# STM32MP23_CM33 register map
File version: 1.2
CPU: CM33 r0p1, little endian, MPU, FPU, vendor SysTick, 8 interrupt priority bits
Registers are 32-bit, read-write, reset 0x0 unless marked. A register's access mark holds for its fields unless they carry their own. Offsets are from the block's base; [hi:lo] are bit positions; {n}, {i} and the like mark numbered series; 'fields as' and 'values as' point back to an identical list.

## RISAF1 — RISAF register block
Base 0x420A0000
Same registers: RISAF2 0x420B0000, RISAF4 0x420D0000, RISAF5 0x420E0000, RISAF1_S 0x520A0000, RISAF2_S 0x520B0000, RISAF4_S 0x520D0000, RISAF5_S 0x520E0000
0x00 RISAF_CR — RISAF configuration register
  [0] GLOCK — Global lock This bit locks the configuration of RISAF registers until next reset. It is cleared by default, and, once set, cannot be reset until global RISAF reset.
    0=RISAF registers are writable; 1=All writes to RISAF registers are ignored, except RISAF_IACR, RISAF_REGx_zCFGR, RISAF_REGx_zSTARTR and RISAF_REGx_zENDR (z = A to B)
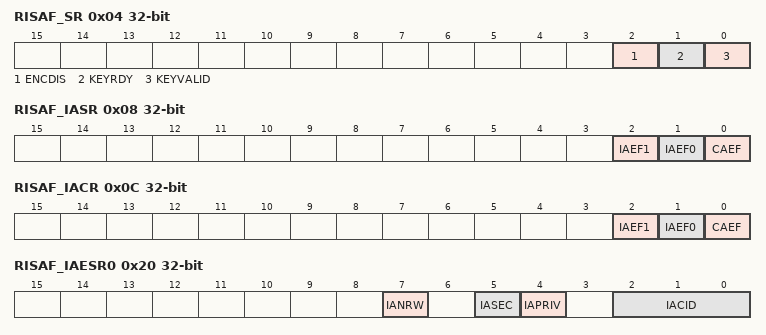
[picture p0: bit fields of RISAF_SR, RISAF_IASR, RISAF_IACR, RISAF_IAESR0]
0x04 RISAF_SR ro — RISAF status register
  [2] ENCDIS — Encryption disabled This bit is reserved if the encryption feature is not available in RISAF (see Section10.3). It is a non-volatile product configuration that cannot be changed by software. Note: If BREN = 0, the AES feature of RISAF is not usable for a given region.
    0=When ENC=BREN=1 in RISAF_REGx_CFGR, all allowed write accesses in region x are encrypted, and all allowed read requests are decrypted; 1=When ENC=BREN=1 in RISAF_REGx_CFGR, all write accesses in region x are ignored, and all read requests return 0. In other words, the AES feature of RISAF is unusable, for any region.
  [1] KEYRDY — Key ready This bit is reserved if the encryption feature is not available in RISAF (see Section10.3).
    0=The most recently written key in RISAF_KEYRy is being expanded; 1=The most recently written key in RISAF_KEYRy is ready for use
  [0] KEYVALID — Key valid This bit is reserved if the encryption feature is not available in RISAF (see Section10.3).
    0=A valid key has not been written in RISAF_KEYRy; 1=A valid key has been written in RISAF_KEYRy
0x08 RISAF_IASR ro — RISAF illegal access status register
  [2] IAEF1 — Illegal access error flag 1 This bit is reserved if the dual port feature is not available in the RISAF instance (see Section10.3). The bit is set when an illegal access is detected by checker unit 1 on the system bus. More details on the error can be found in RISAF_IAESR1 and RISAF_IADDR1. This bit is cleared by setting the corresponding bit in RISAF_IACR.
  [1] IAEF0 — Illegal access error flag 0 This bit is set when an illegal access is detected by checker unit 0 on the system bus. More details on the error can be found in RISAF_IAESR0 and RISAF_IADDR0. This bit is cleared by setting corresponding bit in RISAF_IACR.
  [0] CAEF — Configuration access error flag This bit is set when an illegal access to any RISAF configuration register is detected. It is cleared by setting the corresponding bit in RISAF_IACR.
0x0C RISAF_IACR wo — RISAF illegal access clear register
  [2] IAEF1 — Illegal access error flag 1 This bit is reserved if the dual port feature is not available in the RISAF instance (see Section10.3). Set this bit to clear IAEF1 in RISAF_IASR, allowing the capture of a new error information from RIF gate 1 in RISAF_IAESR1 and RISAF_IADDR1. Note: Clearing this bit does not clear RISAB_IADDR1.
  [1] IAEF0 — Illegal access error flag 0 Set this bit to clear IAEF0 in RISAF_IASR, allowing the capture of a new error information from RIF gate 0 in RISAF_IAESR0 and RISAF_IADDR0 registers. Note: Clearing this bit does not clear RISAB_IADDR0.
  [0] CAEF — Configuration access error flag Set this bit to clear CAEF in RISAF_IASR.
0x20 RISAF_IAESR0 ro — RISAF illegal access error status register 0
  [7] IANRW — Illegal access read/write When IAEFx = 1 in RISAF_IASR, IANRW captures the access type of the illegal access that has been detected by RIF gate x.
    0=Illegal access was a data read or an instruction fetch; 1=Illegal access was a data write
  [5] IASEC — Illegal access security When IAEFx = 1 in RISAF_IASR, IASEC captures the security type of the illegal access that has been detected by RIF gate x.
    0=Illegal access was non-secure; 1=Illegal access was secure
  [4] IAPRIV — Illegal access privileged When IAEFx = 1 in RISAF_IASR, IAPRIV captures the privilege state of the master that issued the illegal access detected by RIF gate x.
    0=Illegal access was unprivileged; 1=Illegal access was privileged
  [2:0] IACID — Illegal access compartment ID When IAEFx = 1 in RISAF_IASR, IACID[2:0] captures the compartment ID of the master that issued the illegal access detected by RIF gate x.
0x24 RISAF_IADDR0 ro — RISAF illegal address register 0
  [31:0] IADD — Illegal address When IAEFx = 1 in RISAFB_IASR, IADD[31:0] captures the address of the erroneous access through RIF gate x. Additional information can be found in RISAF_IAESRx Captured address information is the byte offset from the base of the protected address space.
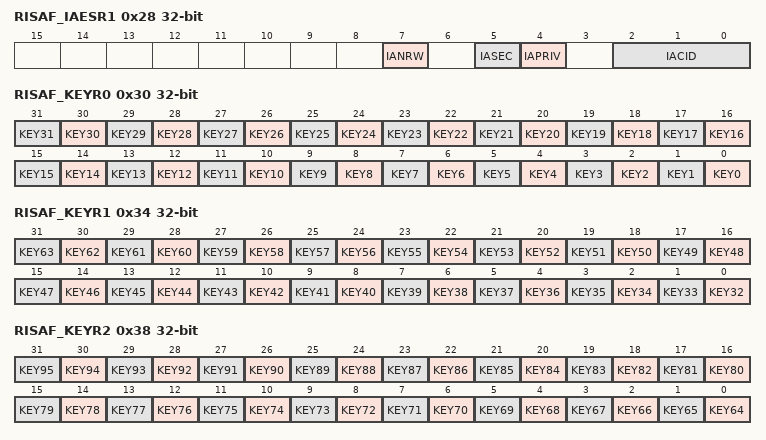
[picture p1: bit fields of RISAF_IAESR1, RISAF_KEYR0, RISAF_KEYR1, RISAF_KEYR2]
0x28 RISAF_IAESR1 ro — RISAF illegal access error status register 1
  fields as RISAF_IAESR0
0x2C RISAF_IADDR1 ro — RISAF illegal address register 1
  fields as RISAF_IADDR0
0x30 RISAF_KEYR0 wo — RISAF encryption key 0
  [n] KEY{n} (n=0..31) — Cryptographic key This write-only bit field contains the key used by the DDRMCE.
0x34 RISAF_KEYR1 wo — RISAF encryption key 1
  [n-32] KEY{n} (n=32..63) — Cryptographic key This write-only bit field contains the key used by the DDRMCE.
0x38 RISAF_KEYR2 wo — RISAF encryption key 2
  [n-64] KEY{n} (n=64..95) — Cryptographic key This write-only bit field contains the key used by the DDRMCE.
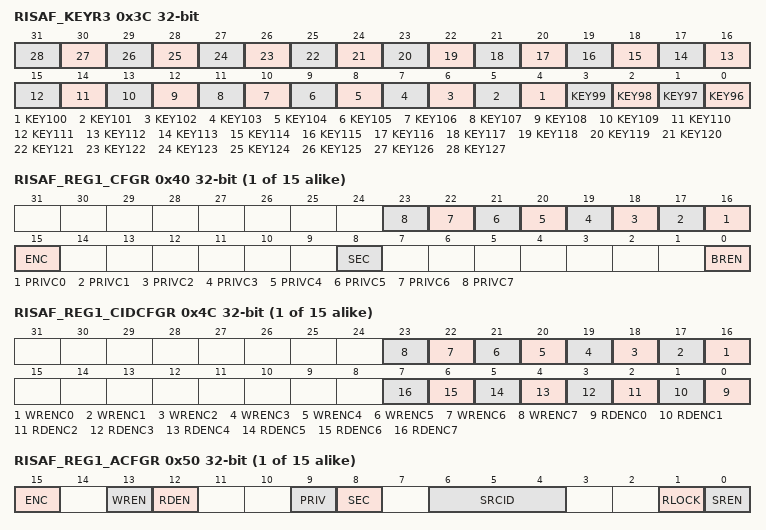
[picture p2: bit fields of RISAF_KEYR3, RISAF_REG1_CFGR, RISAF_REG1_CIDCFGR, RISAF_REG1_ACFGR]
0x3C RISAF_KEYR3 wo — RISAF encryption key 3
  [n-96] KEY{n} (n=96..127) — Cryptographic key This write-only bit field contains the key used by the DDRMCE.
{0x0+0x40*i} RISAF_REG{i}_CFGR (i=1..15) — RISAF region {i} configuration register
  [n+16] PRIVC{n} (n=0..7) — Privileged access for compartment y This bit is taken into account only if BREN = 1.
    0=Application running in compartment y can access to region x in privileged and unprivileged mode; 1=Application running in compartment y can access to region x in privileged mode only
  [15] ENC — Encrypted region This bit is taken into account only if BREN = 1 and if the DDRMCE feature is available in RISAF (see ENCDIS in RISAF_SR and Section10.3). Note: Key registers RISAF_KEYRy must be properly initialized before setting this bit (KEYVALID = 1 in RISAF_SR).
    0=No effect; 1=All allowed write accesses are encrypted and all allowed read requests are decrypted when KEYRDY = 1 in RISAF_SR (to be used for secure regions only)
  [8] SEC — Secure region This bit is taken into account only if BREN = 1.
    0=Only non-secure requests can access region x. SEC value in RISAF_REGx_zCFGR is internally treated as zeroed by RISAF (only non-secure requests to subregions).; 1=Only secure requests can access region x, and optional subregions can be defined as secure or non-secure
  [0] BREN — Base region enable Note: The filtering starts from start address RISAF_REGx_STARTR (included) and ends at end address RISAF_REGx_ENDR (included).
    0=Base region x is disabled. Access control of primary region 0 (secure, privileged, trusted domain TDCID) applies to any access between region x start and end addresses. Associated subregions are also disabled.; 1=Base region x is enabled. Access controls defined in region x apply to any access between region x start and end addresses.
{0x4+0x40*i} RISAF_REG{i}_STARTR (i=1..15) — RISAF region {i} start-address register
  [31:0] BADDSTART — Base region address start This bit field defines the byte-address offset (relative to the base address of the protected address space) of the lowest byte-address in base region x. Address bits less than the granularity and greater than the protected address space size cannot be written to, and remain 0.
{0x8+0x40*i} RISAF_REG{i}_ENDR reset 0xFF (i=1..15) — RISAF region {i} end-address register
  [31:0] BADDEND — Base region address end This bit field defines the byte-address offset (relative to the base address of the protected address space) of the highest byte-address in base region x. Address bits less than the granularity cannot be modified, and remain 1. Address bits greater than the protected address space size cannot be written, and remain 0.
{0xC+0x40*i} RISAF_REG{i}_CIDCFGR (i=1..15) — RISAF region {i} CID configuration register
  [n+16] WRENC{n} (n=0..7) — Write enable for compartment y This bit is taken into account only if BREN = 1 in RISAF_REGx_CFGR. by SEC and PRIVCy in RISAF_REGx_CFGR, also applies.
    0=Application running in compartment y cannot write to region x (write ignored); 1=Application running in compartment y can write to region x. Additional control defined
  [n] RDENC{n} (n=0..7) — Read enable for compartment y This bit is taken into account only if BREN = 1 in RISAF_REGx_CFGR.
    0=Application running in compartment y cannot read region x (read as 0); 1=Application running in compartment y can read region x. Additional control defined by SEC and PRIVCy in RISAF_REGx_CFGR, also applies.
{0x10+0x40*i} RISAF_REG{i}_ACFGR (i=1..15) — RISAF region {i} subregion z configuration register
  [15] ENC ro — Encrypted subregion This read-only bit is a mirror to ENC in RISAF_REGx_CFGR. It is reserved if the encryption feature is not available in RISAF (see ENCDIS in RISAF_SR, and Section10.3). (resp. encrypted)
    0=No effect; 1=All allowed read (resp. write) requests to subregion z of region x are decrypted
  [13] WREN — Write enable This bit is taken into account only if SREN = 1 in this register.
    0=Any writes to subregion z of region x are ignored; 1=Subregion z of region x can be written to
  [12] RDEN — Read enable This bit is taken into account only if SREN = 1 in this register.
    0=Any read to subregion z of region x returns 0; 1=Subregion z of region x can be read
  [9] PRIV — Privileged subregion This bit is taken into account only if SREN = 1 in this register. Note: When base region x is defined as unprivileged for the SCID compartment (PRIVCy = 0 in RISAF_REGx_CFGR, with SRCID = Cy), unprivileged accesses to the subregion z are always granted.
    0=Privileged and unprivileged accesses are granted in subregion z of region x; 1=Only privileged accesses are granted in subregion z of region x
  [8] SEC — Secure subregion This bit is taken into account only if SREN = 1 in this register. Non-secure modification to it are discarded. Note: When base region x is defined as non-secure (SEC = 0 in RISAF_REGx_CFGR), only non-secure accesses to the subregion z are granted.
    0=Only non-secure requests can access subregion z of region x; 1=Only secure requests can access subregion z of region x
  [6:4] SRCID — Subregion CID When SREN = 1 in this register, SRCID[2:0] defines which compartment has access to the subregion z of RISAF region x.
  [1] RLOCK — Resource lock When this bit is set, the subregion resource is locked. Note: This bit is set once, cleared only by RISAF reset. It cannot be set if GLOCK = 0 in RISAF_CR.
    0=RISAF_REGx_zCFGR, RISAF_REGx_zSTARTR, and RISAF_REGx_zENDR are writable; 1=Writes to RISAF_REGx_zCFGR, RISAF_REGx_zSTARTR, and RISAF_REGx_zENDR are ignored
  [0] SREN — Subregion enable Note: The filtering starts from address RISAF_REGx_zSTARTR (included), and ends at address RISAF_REGx_zENDR (included).
    0=Subregion z is disabled. Access control of base region x applies to any access between this subregion start and end addresses.; 1=Subregion z of region x is enabled. Access control defined in subregion z applies to any access between subregion z start and end addresses.
{0x14+0x40*i} RISAF_REG{i}_ASTARTR (i=1..15) — RISAF region {i} subregion z start-address register
  [31:0] SADDSTART — Subregion address start This bit field defines the byte-address offset (relative to the base address of the protected address space) of the lowest byte-address in subregion z in base region x. Address bits less than the granularity and greater than the protected address space size cannot be written, and remain 0. The effective subregion is the intersection of the subregion and its base region. So there is no point in programming SADDSTART to be below the associated BADDSTART.
{0x18+0x40*i} RISAF_REG{i}_AENDR reset 0xFF (i=1..15) — RISAF region {i} subregion z end-address register
  [31:0] SADDEND — Subregion address end This bit field defines the byte-address offset (relative to the base address of the protected address space) of the highest byte-address of subregion z in base region x. Address bits less than the granularity cannot be modified, and remain 1. Address bits greater than the protected address space size cannot be written, and remain 0. The effective subregion is the intersection of the subregion and its base region. So there is no point in programming SADDEND to be higher than the associated BADDEND.
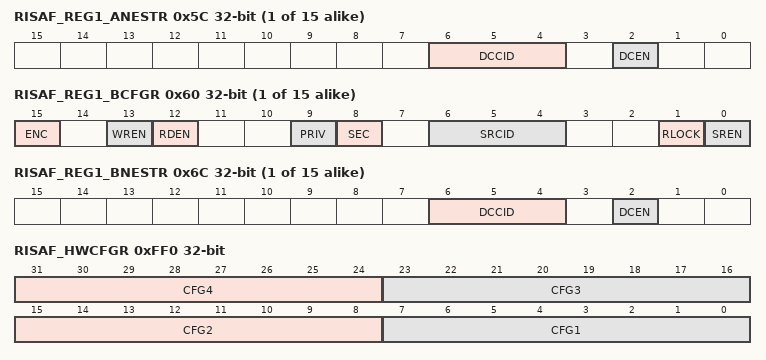
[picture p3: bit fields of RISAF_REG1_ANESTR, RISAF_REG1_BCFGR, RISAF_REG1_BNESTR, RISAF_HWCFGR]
{0x1C+0x40*i} RISAF_REG{i}_ANESTR (i=1..15) — RISAF region {i} subregion z nested mode register
  [6:4] DCCID — Delegated configuration CID The trusted domain can use this bit field to statically define which compartment can program the RIF configuration of subregion z if DCEN = 1in this register.
  [2] DCEN — Delegated configuration enable Note: RIF configuration of subregion z is defined as RISAF_REGx_zCFGR, RISAF_REGx_STARTR, and RISAF_REGx_ENDR.
    0=RIF configuration for subregion z can be written only by the trusted domain; 1=RIF configuration for subregion z can be written only by compartment DCCID, defined in this register. If base region x is defined as secure (SEC = 1), non-secure write accesses to this subregion RIF configuration by compartment DCCID are ignored.
{0x20+0x40*i} RISAF_REG{i}_BCFGR (i=1..15) — RISAF region {i} subregion z configuration register
  fields as RISAF_REG1_ACFGR
{0x24+0x40*i} RISAF_REG{i}_BSTARTR (i=1..15) — RISAF region {i} subregion z start-address register
  fields as RISAF_REG1_ASTARTR
{0x28+0x40*i} RISAF_REG{i}_BENDR reset 0xFF (i=1..15) — RISAF region {i} subregion z end-address register
  fields as RISAF_REG1_AENDR
{0x2C+0x40*i} RISAF_REG{i}_BNESTR (i=1..15) — RISAF region {i} subregion z nested mode register
  fields as RISAF_REG1_ANESTR
0xFF0 RISAF_HWCFGR ro reset not defined — RISAF hardware configuration register
  [31:24] CFG4 — Hardware generic 4 This bit field returns the number of address bits to match when determining access to a base region or subregion (WIDTH).
  [23:16] CFG3 — Hardware generic 3 This bit field returns the smallest possible region size (granularity) (LOG_BLOCKSIZE).
  [15:8] CFG2 — Hardware generic 2 This bit field returns the total number of subregions A and B (NUM_SUBREGIONAS, NUM_SUBREGIONBS).
  [7:0] CFG1 — Hardware generic 1 This bit field returns the number of base regions (NUM_REGS).
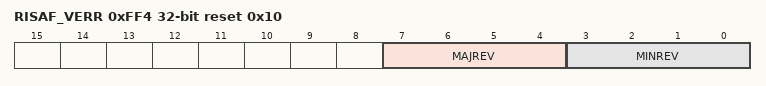
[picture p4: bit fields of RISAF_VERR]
0xFF4 RISAF_VERR ro reset 0x10 — RISAF version register
  [7:4] MAJREV — RISAF major revision
  [3:0] MINREV — RISAF minor revision
0xFF8 RISAF_IPIDR ro reset 0x100160 (reset mask 0xFFFFFFF0) — RISAF identification register
  [31:0] ID — RISAF identification code
0xFFC RISAF_SIDR ro reset 0xA3C5DD01 — RISAF size identification register
  [31:0] SID — RISAF size identification code Bits[31:8] = 0xA3C5DD (fixed code) Bits[7:0] = 0x01 (1-Kbyte address decoding)
